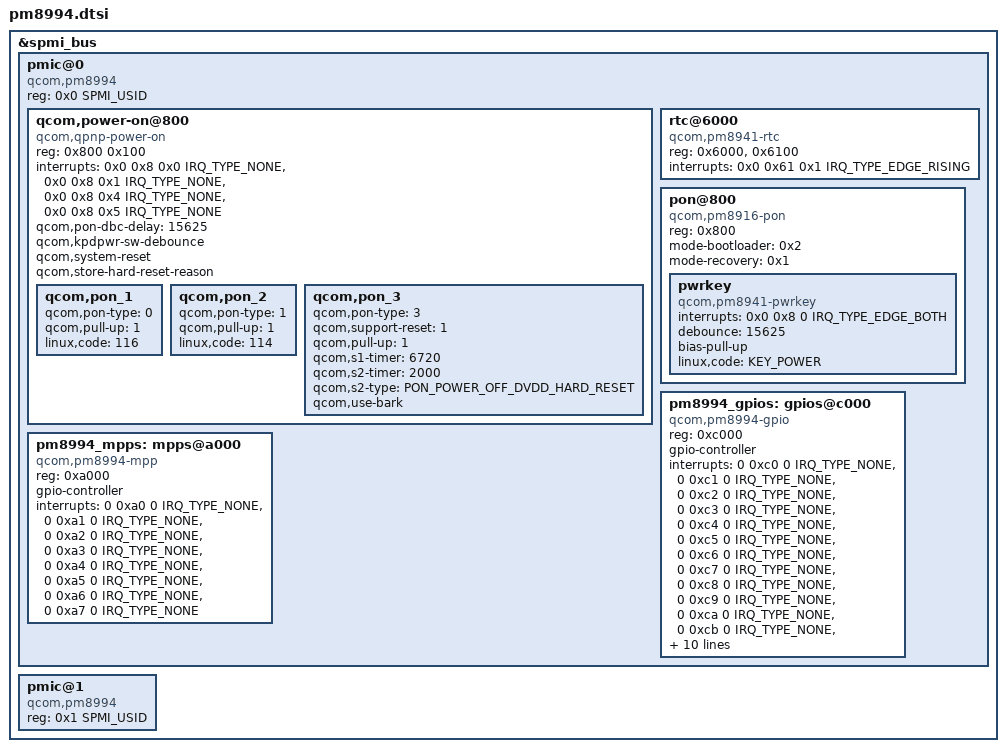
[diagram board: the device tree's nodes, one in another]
// SPDX-License-Identifier: GPL-2.0
#include <dt-bindings/interrupt-controller/irq.h>
#include <dt-bindings/spmi/spmi.h>
#include <dt-bindings/input/linux-event-codes.h>
#include <dt-bindings/power/power-on.h>

&spmi_bus {

	pmic@0 {
		compatible = "qcom,pm8994", "qcom,spmi-pmic";
		reg = <0x0 SPMI_USID>;
		#address-cells = <1>;
		#size-cells = <0>;

		qcom,power-on@800 {
                         compatible = "qcom,qpnp-power-on";
                         reg = <0x800 0x100>;
                         interrupts = <0x0 0x8 0x0 IRQ_TYPE_NONE>,
                                      <0x0 0x8 0x1 IRQ_TYPE_NONE>,
                                      <0x0 0x8 0x4 IRQ_TYPE_NONE>,
                                      <0x0 0x8 0x5 IRQ_TYPE_NONE>;
                         interrupt-names = "kpdpwr", "resin",
                                         "resin-bark", "kpdpwr-resin-bark";
                         qcom,pon-dbc-delay = <15625>;
                         qcom,kpdpwr-sw-debounce;
                         qcom,system-reset;
                         qcom,store-hard-reset-reason;

                         qcom,pon_1 {
                                 qcom,pon-type = <0>;
                                 qcom,pull-up = <1>;
                                 linux,code = <116>;
                         };

                         qcom,pon_2 {
                                 qcom,pon-type = <1>;
                                 qcom,pull-up = <1>;
                                 linux,code = <114>;
                         };

                         qcom,pon_3 {
                                 qcom,pon-type = <3>;
                                 qcom,support-reset = <1>;
                                 qcom,pull-up = <1>;
                                 qcom,s1-timer = <6720>;
                                 qcom,s2-timer = <2000>;
                                 qcom,s2-type = <PON_POWER_OFF_DVDD_HARD_RESET>;
                                 qcom,use-bark;
			};
		};

		rtc@6000 {
			compatible = "qcom,pm8941-rtc";
			reg = <0x6000>, <0x6100>;
			reg-names = "rtc", "alarm";
			interrupts = <0x0 0x61 0x1 IRQ_TYPE_EDGE_RISING>;
		};

		pon@800 {
			compatible = "qcom,pm8916-pon";

			reg = <0x800>;
			mode-bootloader = <0x2>;
			mode-recovery = <0x1>;

			pwrkey {
				compatible = "qcom,pm8941-pwrkey";
				interrupts = <0x0 0x8 0 IRQ_TYPE_EDGE_BOTH>;
				debounce = <15625>;
				bias-pull-up;
				linux,code = <KEY_POWER>;
			};

		};

		pm8994_gpios: gpios@c000 {
			compatible = "qcom,pm8994-gpio";
			reg = <0xc000>;
			gpio-controller;
			#gpio-cells = <2>;
			interrupts = <0 0xc0 0 IRQ_TYPE_NONE>,
				     <0 0xc1 0 IRQ_TYPE_NONE>,
				     <0 0xc2 0 IRQ_TYPE_NONE>,
				     <0 0xc3 0 IRQ_TYPE_NONE>,
				     <0 0xc4 0 IRQ_TYPE_NONE>,
				     <0 0xc5 0 IRQ_TYPE_NONE>,
				     <0 0xc6 0 IRQ_TYPE_NONE>,
				     <0 0xc7 0 IRQ_TYPE_NONE>,
				     <0 0xc8 0 IRQ_TYPE_NONE>,
				     <0 0xc9 0 IRQ_TYPE_NONE>,
				     <0 0xca 0 IRQ_TYPE_NONE>,
				     <0 0xcb 0 IRQ_TYPE_NONE>,
				     <0 0xcc 0 IRQ_TYPE_NONE>,
				     <0 0xcd 0 IRQ_TYPE_NONE>,
				     <0 0xce 0 IRQ_TYPE_NONE>,
				     <0 0xcf 0 IRQ_TYPE_NONE>,
				     <0 0xd0 0 IRQ_TYPE_NONE>,
				     <0 0xd1 0 IRQ_TYPE_NONE>,
				     <0 0xd2 0 IRQ_TYPE_NONE>,
				     <0 0xd3 0 IRQ_TYPE_NONE>,
				     <0 0xd4 0 IRQ_TYPE_NONE>,
				     <0 0xd5 0 IRQ_TYPE_NONE>;
		};

		pm8994_mpps: mpps@a000 {
			compatible = "qcom,pm8994-mpp";
			reg = <0xa000>;
			gpio-controller;
			#gpio-cells = <2>;
			interrupts = <0 0xa0 0 IRQ_TYPE_NONE>,
				     <0 0xa1 0 IRQ_TYPE_NONE>,
				     <0 0xa2 0 IRQ_TYPE_NONE>,
				     <0 0xa3 0 IRQ_TYPE_NONE>,
				     <0 0xa4 0 IRQ_TYPE_NONE>,
				     <0 0xa5 0 IRQ_TYPE_NONE>,
				     <0 0xa6 0 IRQ_TYPE_NONE>,
				     <0 0xa7 0 IRQ_TYPE_NONE>;
		};
	};

	pmic@1 {
		compatible = "qcom,pm8994", "qcom,spmi-pmic";
		reg = <0x1 SPMI_USID>;
		#address-cells = <1>;
		#size-cells = <0>;
	};
};
